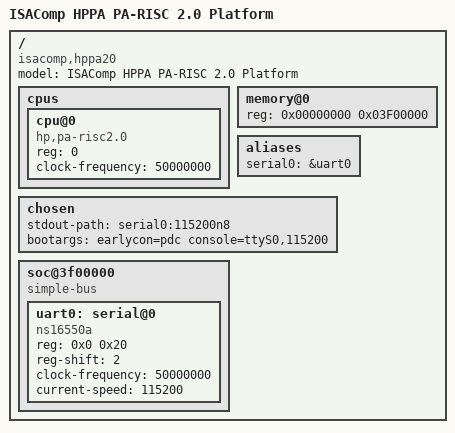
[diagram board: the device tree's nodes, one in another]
// SPDX-License-Identifier: GPL-2.0
// Device tree for HPPA (PA-RISC 2.0) processor generated by ISAComp
// Platform: Verilator simulation with NS16550A UART
/dts-v1/;

/ {
	compatible = "isacomp,hppa20";
	model = "ISAComp HPPA PA-RISC 2.0 Platform";

	#address-cells = <1>;
	#size-cells = <1>;

	cpus {
		#address-cells = <1>;
		#size-cells = <0>;

		cpu@0 {
			device_type = "cpu";
			compatible = "hp,pa-risc2.0";
			reg = <0>;
			clock-frequency = <50000000>;  // 50 MHz
		};
	};

	// 63MB memory starting at physical address 0
	memory@0 {
		device_type = "memory";
		reg = <0x00000000 0x03F00000>;  // 63MB
	};

	aliases {
		serial0 = &uart0;
	};

	chosen {
		stdout-path = "serial0:115200n8";
		bootargs = "earlycon=pdc console=ttyS0,115200";
	};

	soc@3f00000 {
		compatible = "simple-bus";
		ranges = <0 0x03F00000 0x100000>;

		#address-cells = <1>;
		#size-cells = <1>;

		uart0: serial@0 {
			compatible = "ns16550a";
			reg = <0x0 0x20>;
			reg-shift = <2>;
			clock-frequency = <50000000>;
			current-speed = <115200>;
		};
	};
};
